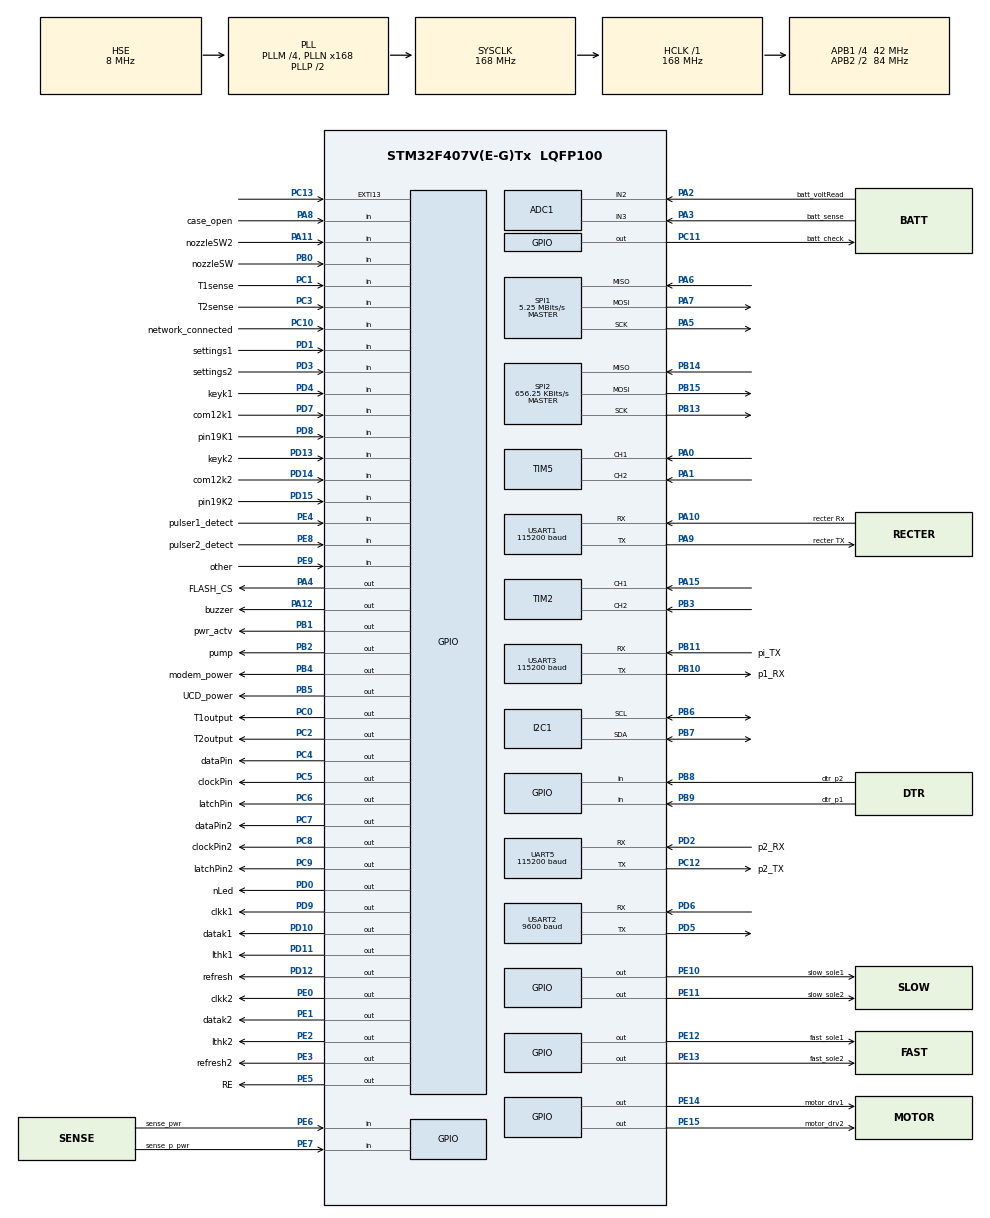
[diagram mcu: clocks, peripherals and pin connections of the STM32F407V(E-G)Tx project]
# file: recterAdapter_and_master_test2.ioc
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ADC1.Channel-1\#ChannelRegularConversion=ADC_CHANNEL_2
ADC1.ContinuousConvMode=ENABLE
ADC1.DMAContinuousRequests=DISABLE
ADC1.NbrOfConversion=1
ADC1.NbrOfConversionFlag=1
ADC1.Rank-1\#ChannelRegularConversion=1
ADC1.SamplingTime-1\#ChannelRegularConversion=ADC_SAMPLETIME_28CYCLES
ADC1.ScanConvMode=ENABLE
ADC1.master=1
Dma.ADC1.0.Direction=DMA_PERIPH_TO_MEMORY
Dma.ADC1.0.FIFOMode=DMA_FIFOMODE_DISABLE
Dma.ADC1.0.Instance=DMA2_Stream0
Dma.ADC1.0.MemDataAlignment=DMA_MDATAALIGN_HALFWORD
Dma.ADC1.0.MemInc=DMA_MINC_ENABLE
Dma.ADC1.0.Mode=DMA_CIRCULAR
Dma.ADC1.0.PeriphDataAlignment=DMA_PDATAALIGN_HALFWORD
Dma.ADC1.0.PeriphInc=DMA_PINC_DISABLE
Dma.ADC1.0.Priority=DMA_PRIORITY_LOW
Dma.Request0=ADC1
Dma.Request1=USART2_RX
Dma.Request2=USART2_TX
Dma.USART2_RX.1.Direction=DMA_PERIPH_TO_MEMORY
Dma.USART2_RX.1.FIFOMode=DMA_FIFOMODE_DISABLE
Dma.USART2_RX.1.Instance=DMA1_Stream5
Dma.USART2_RX.1.MemDataAlignment=DMA_MDATAALIGN_BYTE
Dma.USART2_RX.1.MemInc=DMA_MINC_ENABLE
Dma.USART2_RX.1.Mode=DMA_NORMAL
Dma.USART2_RX.1.PeriphDataAlignment=DMA_PDATAALIGN_BYTE
Dma.USART2_RX.1.PeriphInc=DMA_PINC_DISABLE
Dma.USART2_RX.1.Priority=DMA_PRIORITY_LOW
Dma.USART2_TX.2.Direction=DMA_MEMORY_TO_PERIPH
Dma.USART2_TX.2.FIFOMode=DMA_FIFOMODE_DISABLE
Dma.USART2_TX.2.Instance=DMA1_Stream6
Dma.USART2_TX.2.MemDataAlignment=DMA_MDATAALIGN_BYTE
Dma.USART2_TX.2.MemInc=DMA_MINC_ENABLE
Dma.USART2_TX.2.Mode=DMA_NORMAL
Dma.USART2_TX.2.PeriphDataAlignment=DMA_PDATAALIGN_BYTE
Dma.USART2_TX.2.PeriphInc=DMA_PINC_DISABLE
Dma.USART2_TX.2.Priority=DMA_PRIORITY_LOW
IWDG.Prescaler=IWDG_PRESCALER_32
IWDG.Reload=799
Mcu.Family=STM32F4
Mcu.Name=STM32F407V(E-G)Tx
Mcu.Package=LQFP100
NVIC.DMA1_Stream5_IRQn=true\:0\:0\:false\:false\:true\:false\:true\:true
NVIC.DMA1_Stream6_IRQn=true\:0\:0\:false\:false\:true\:false\:true\:true
NVIC.DMA2_Stream0_IRQn=true\:0\:0\:false\:false\:true\:false\:true\:true
NVIC.EXTI15_10_IRQn=true\:0\:0\:false\:false\:true\:true\:true\:true
NVIC.HASH_RNG_IRQn=true\:0\:0\:false\:false\:true\:true\:true\:true
NVIC.I2C1_ER_IRQn=true\:0\:0\:false\:false\:true\:true\:true\:true
NVIC.I2C1_EV_IRQn=true\:0\:0\:false\:false\:true\:true\:true\:true
NVIC.PriorityGroup=NVIC_PRIORITYGROUP_4
NVIC.RTC_WKUP_IRQn=true\:0\:0\:false\:false\:true\:true\:true\:true
NVIC.SPI2_IRQn=true\:0\:0\:false\:false\:true\:true\:true\:true
NVIC.UART5_IRQn=true\:0\:0\:false\:false\:true\:true\:true\:true
NVIC.USART1_IRQn=true\:0\:0\:false\:false\:true\:true\:true\:true
NVIC.USART2_IRQn=true\:0\:0\:false\:false\:true\:true\:true\:true
NVIC.USART3_IRQn=true\:0\:0\:false\:false\:true\:true\:true\:true
PA0-WKUP.Signal=S_TIM5_CH1
PA1.Signal=S_TIM5_CH2
PA10.GPIO_Label=recter Rx
PA10.Mode=Asynchronous
PA10.Signal=USART1_RX
PA11.GPIO_Label=nozzleSW2
PA11.GPIO_PuPd=GPIO_PULLUP
PA11.Signal=GPIO_Input
PA12.GPIO_Label=buzzer
PA12.Signal=GPIO_Output
PA13.Mode=Serial_Wire
PA13.Signal=SYS_JTMS-SWDIO
PA14.Mode=Serial_Wire
PA14.Signal=SYS_JTCK-SWCLK
PA15.Signal=S_TIM2_CH1_ETR
PA2.GPIO_Label=batt_voltRead
PA2.Signal=ADCx_IN2
PA3.GPIO_Label=batt_sense
PA3.Signal=ADCx_IN3
PA4.GPIO_Label=FLASH_CS
PA4.PinState=GPIO_PIN_SET
PA4.Signal=GPIO_Output
PA5.Mode=Full_Duplex_Master
PA5.Signal=SPI1_SCK
PA6.Mode=Full_Duplex_Master
PA6.Signal=SPI1_MISO
PA7.Mode=Full_Duplex_Master
PA7.Signal=SPI1_MOSI
PA8.GPIO_Label=case_open
PA8.Signal=GPIO_Input
PA9.GPIO_Label=recter TX
PA9.Mode=Asynchronous
PA9.Signal=USART1_TX
PB0.GPIO_Label=nozzleSW
PB0.GPIO_PuPd=GPIO_PULLUP
PB0.Signal=GPIO_Input
PB1.GPIO_Label=pwr_actv
PB1.Signal=GPIO_Output
PB10.GPIO_Label=p1_RX
PB10.Mode=Asynchronous
PB10.Signal=USART3_TX
PB11.GPIO_Label=pi_TX
PB11.Mode=Asynchronous
PB11.Signal=USART3_RX
PB12.Signal=SPI2_NSS
PB13.Mode=Full_Duplex_Master
PB13.Signal=SPI2_SCK
PB14.Mode=Full_Duplex_Master
PB14.Signal=SPI2_MISO
PB15.Mode=Full_Duplex_Master
PB15.Signal=SPI2_MOSI
PB2.GPIO_Label=pump
PB2.Signal=GPIO_Output
PB3.Signal=S_TIM2_CH2
PB4.GPIO_Label=modem_power
PB4.Signal=GPIO_Output
PB5.GPIO_Label=UCD_power
PB5.Signal=GPIO_Output
PB6.Mode=I2C
PB6.Signal=I2C1_SCL
PB7.Mode=I2C
PB7.Signal=I2C1_SDA
PB8.GPIO_Label=dtr_p2
PB8.GPIO_PuPd=GPIO_PULLUP
PB8.Signal=GPIO_Input
PB9.GPIO_Label=dtr_p1
PB9.GPIO_PuPd=GPIO_PULLUP
PB9.Signal=GPIO_Input
PC0.GPIO_Label=T1output
PC0.Signal=GPIO_Output
PC1.GPIO_Label=T1sense
PC1.Signal=GPIO_Input
PC10.GPIO_Label=network_connected
PC10.GPIO_PuPd=GPIO_PULLDOWN
PC10.Signal=GPIO_Input
PC11.GPIO_Label=batt_check
PC11.Signal=GPIO_Output
PC12.GPIO_Label=p2_TX
PC12.Mode=Asynchronous
PC12.Signal=UART5_TX
PC13-ANTI_TAMP.Signal=GPXTI13
PC14-OSC32_IN.Mode=LSE-External-Oscillator
PC14-OSC32_IN.Signal=RCC_OSC32_IN
PC15-OSC32_OUT.Mode=LSE-External-Oscillator
PC15-OSC32_OUT.Signal=RCC_OSC32_OUT
PC2.GPIO_Label=T2output
PC2.Signal=GPIO_Output
PC3.GPIO_Label=T2sense
PC3.Signal=GPIO_Input
PC4.GPIO_Label=dataPin
PC4.Signal=GPIO_Output
PC5.GPIO_Label=clockPin
PC5.Signal=GPIO_Output
PC6.GPIO_Label=latchPin
PC6.Signal=GPIO_Output
PC7.GPIO_Label=dataPin2
PC7.Signal=GPIO_Output
PC8.GPIO_Label=clockPin2
PC8.Signal=GPIO_Output
PC9.GPIO_Label=latchPin2
PC9.Signal=GPIO_Output
PD0.GPIO_Label=nLed
PD0.Signal=GPIO_Output
PD1.GPIO_Label=settings1
PD1.GPIO_PuPd=GPIO_PULLUP
PD1.Signal=GPIO_Input
PD10.GPIO_Label=datak1
PD10.Signal=GPIO_Output
PD11.GPIO_Label=lthk1
PD11.Signal=GPIO_Output
PD12.GPIO_Label=refresh
PD12.Signal=GPIO_Output
PD13.GPIO_Label=keyk2
PD13.GPIO_PuPd=GPIO_PULLUP
PD13.Signal=GPIO_Input
PD14.GPIO_Label=com12k2
PD14.GPIO_PuPd=GPIO_PULLUP
PD14.Signal=GPIO_Input
PD15.GPIO_Label=pin19K2
PD15.GPIO_PuPd=GPIO_PULLUP
PD15.Signal=GPIO_Input
PD2.GPIO_Label=p2_RX
PD2.Mode=Asynchronous
PD2.Signal=UART5_RX
PD3.GPIO_Label=settings2
PD3.GPIO_PuPd=GPIO_PULLUP
PD3.Signal=GPIO_Input
PD4.GPIO_Label=keyk1
PD4.GPIO_PuPd=GPIO_PULLUP
PD4.Signal=GPIO_Input
PD5.Mode=Asynchronous
PD5.Signal=USART2_TX
PD6.Mode=Asynchronous
PD6.Signal=USART2_RX
PD7.GPIO_Label=com12k1
PD7.GPIO_PuPd=GPIO_PULLUP
PD7.Signal=GPIO_Input
PD8.GPIO_Label=pin19K1
PD8.GPIO_PuPd=GPIO_PULLUP
PD8.Signal=GPIO_Input
PD9.GPIO_Label=clkk1
PD9.Signal=GPIO_Output
PE0.GPIO_Label=clkk2
PE0.Signal=GPIO_Output
PE1.GPIO_Label=datak2
PE1.Signal=GPIO_Output
PE10.GPIO_Label=slow_sole1
PE10.PinState=GPIO_PIN_RESET
PE10.Signal=GPIO_Output
PE11.GPIO_Label=slow_sole2
PE11.PinState=GPIO_PIN_RESET
PE11.Signal=GPIO_Output
PE12.GPIO_Label=fast_sole1
PE12.PinState=GPIO_PIN_RESET
PE12.Signal=GPIO_Output
PE13.GPIO_Label=fast_sole2
PE13.PinState=GPIO_PIN_RESET
PE13.Signal=GPIO_Output
PE14.GPIO_Label=motor_drv1
PE14.PinState=GPIO_PIN_RESET
PE14.Signal=GPIO_Output
PE15.GPIO_Label=motor_drv2
PE15.PinState=GPIO_PIN_RESET
PE15.Signal=GPIO_Output
PE2.GPIO_Label=lthk2
PE2.Signal=GPIO_Output
PE3.GPIO_Label=refresh2
PE3.Signal=GPIO_Output
PE4.GPIO_Label=pulser1_detect
PE4.Signal=GPIO_Input
PE5.GPIO_Label=RE
PE5.Signal=GPIO_Output
PE6.GPIO_Label=sense_pwr
PE6.GPIO_PuPd=GPIO_PULLUP
PE6.Signal=GPIO_Input
PE7.GPIO_Label=sense_p_pwr
PE7.GPIO_PuPd=GPIO_NOPULL
PE7.Signal=GPIO_Input
PE8.GPIO_Label=pulser2_detect
PE8.Signal=GPIO_Input
PE9.GPIO_Label=other
PE9.Signal=GPIO_Input
PH0-OSC_IN.Mode=HSE-External-Oscillator
PH0-OSC_IN.Signal=RCC_OSC_IN
PH1-OSC_OUT.Mode=HSE-External-Oscillator
PH1-OSC_OUT.Signal=RCC_OSC_OUT
ProjectManager.HeapSize=0x1890
ProjectManager.StackSize=0x1AD0
ProjectManager.TargetToolchain=STM32CubeIDE
RCC.48MHZClocksFreq_Value=48000000
RCC.AHBFreq_Value=168000000
RCC.APB1CLKDivider=RCC_HCLK_DIV4
RCC.APB1Freq_Value=42000000
RCC.APB1TimFreq_Value=84000000
RCC.APB2CLKDivider=RCC_HCLK_DIV2
RCC.APB2Freq_Value=84000000
RCC.APB2TimFreq_Value=168000000
RCC.CortexFreq_Value=168000000
RCC.HCLKFreq_Value=168000000
RCC.HSE_VALUE=8000000
RCC.HSI_VALUE=16000000
RCC.PLLM=4
RCC.PLLN=168
RCC.PLLQ=7
RCC.PLLSourceVirtual=RCC_PLLSOURCE_HSE
RCC.RCC_RTC_Clock_SourceVirtual=RCC_RTCCLKSOURCE_LSE
RCC.RCC_RTC_Clock_Source_FROM_HSE=RCC_RTCCLKSOURCE_HSE_DIV8
RCC.SYSCLKFreq_VALUE=168000000
RCC.SYSCLKSource=RCC_SYSCLKSOURCE_PLLCLK
RCC.VCOOutputFreq_Value=336000000
RTC.Date=26
RTC.Hours=13
RTC.Month=RTC_MONTH_SEPTEMBER
RTC.Year=22
SH.ADCx_IN2.0=ADC1_IN2,IN2
SH.ADCx_IN3.0=ADC1_IN3,IN3
SH.S_TIM2_CH1_ETR.0=TIM2_CH1,Encoder_Interface
SH.S_TIM2_CH2.0=TIM2_CH2,Encoder_Interface
SH.S_TIM5_CH1.0=TIM5_CH1,Encoder_Interface
SH.S_TIM5_CH2.0=TIM5_CH2,Encoder_Interface
SPI1.BaudRatePrescaler=SPI_BAUDRATEPRESCALER_16
SPI1.CalculateBaudRate=5.25 MBits/s
SPI1.Direction=SPI_DIRECTION_2LINES
SPI1.Mode=SPI_MODE_MASTER
SPI1.VirtualType=VM_MASTER
SPI2.BaudRatePrescaler=SPI_BAUDRATEPRESCALER_64
SPI2.CalculateBaudRate=656.25 KBits/s
SPI2.Direction=SPI_DIRECTION_2LINES
SPI2.Mode=SPI_MODE_MASTER
SPI2.VirtualType=VM_MASTER
TIM2.EncoderMode=TIM_ENCODERMODE_TI12
TIM2.IC1Filter=10
TIM2.IC2Filter=10
TIM5.EncoderMode=TIM_ENCODERMODE_TI12
TIM5.IC1Filter=10
TIM5.IC2Filter=10
UART5.BaudRate=115200
UART5.VirtualMode=Asynchronous
USART1.BaudRate=115200
USART1.VirtualMode=VM_ASYNC
USART2.BaudRate=9600
USART2.Parity=PARITY_ODD
USART2.VirtualMode=VM_ASYNC
USART2.WordLength=WORDLENGTH_9B
USART3.BaudRate=115200
USART3.VirtualMode=VM_ASYNC
VP_IWDG_VS_IWDG.Mode=IWDG_Activate
VP_RNG_VS_RNG.Mode=RNG_Activate
VP_RTC_VS_RTC_Activate.Mode=RTC_Enabled
VP_RTC_VS_RTC_Calendar.Mode=RTC_Calendar
VP_RTC_VS_RTC_WakeUp_intern.Mode=WakeUp
board=custom

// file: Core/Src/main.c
/* USER CODE BEGIN Header */
/**
 ******************************************************************************
 * @file           : main.c
 * @brief          : Main program body
 ******************************************************************************
 * @attention
 *
 * <h2><center>&copy; Copyright (c) 2021 STMicroelectronics.
 * All rights reserved.</center></h2>
 *
 * This software component is licensed by ST under BSD 3-Clause license,
 * the "License"; You may not use this file except in compliance with the
 * License. You may obtain a copy of the License at:
 *                        opensource.org/licenses/BSD-3-Clause
 *
 ******************************************************************************
 */
/* USER CODE END Header */
#include "main.h"

/* USER CODE BEGIN Includes */

#include "thread1.h"
#include "interrupt_codes.h"
#include "write__.h"
#include "stdio.h"
#include "myLibraries.h"
#include "string.h"
#include "stdbool.h"

#include "UartRingbuffer.h"

#include "core_cm4.h" // CMSIS header for Cortex-M4

/* USER CODE END Includes */

ADC_HandleTypeDef hadc1;
DMA_HandleTypeDef hdma_adc1;

I2C_HandleTypeDef hi2c1;

IWDG_HandleTypeDef hiwdg;

RNG_HandleTypeDef hrng;

RTC_HandleTypeDef hrtc;

SPI_HandleTypeDef hspi1;
SPI_HandleTypeDef hspi2;

TIM_HandleTypeDef htim2;
TIM_HandleTypeDef htim5;

UART_HandleTypeDef huart5;
UART_HandleTypeDef huart1;
UART_HandleTypeDef huart2;
UART_HandleTypeDef huart3;
DMA_HandleTypeDef hdma_usart2_rx;
DMA_HandleTypeDef hdma_usart2_tx;

/* USER CODE BEGIN PV */
extern uint32_t pulser1;
extern uint32_t pulser2;
extern char prn[40];

extern pump_settings_stream1 settings_stream1[2];
extern pump_settings_stream2 settings_stream2[2];

//uint8_t dummyValue = 0;

ADC_ChannelConfTypeDef sConfig = {0};

uint32_t start_cycles = 0,
		 end_cycles = 0,
		 elapsed_cycles = 0;

float time_us = 0.0; // Time in microseconds

/* USER CODE END PV */

void SystemClock_Config(void);
static void MX_GPIO_Init(void);
static void MX_DMA_Init(void);
static void MX_I2C1_Init(void);
static void MX_RTC_Init(void);
static void MX_SPI1_Init(void);
static void MX_SPI2_Init(void);
static void MX_TIM2_Init(void);
static void MX_TIM5_Init(void);
static void MX_USART1_UART_Init(void);
static void MX_USART2_UART_Init(void);
static void MX_ADC1_Init(void);
static void MX_USART3_UART_Init(void);
static void MX_UART5_Init(void);
static void MX_RNG_Init(void);
static void MX_IWDG_Init(void);
/* USER CODE BEGIN PFP */

// This array hold the the channels ADC value
volatile uint16_t adc_dma_result[2];
// This variable calculate the array length.
// In our case, array size in 3
int adc_channel_count = sizeof(adc_dma_result)/sizeof(adc_dma_result[0]);
// This flag will help to detect
// the DMA conversion completed or not
uint8_t adc_conv_complete_flag = 0;

// This character buffer array will
// store the result after conversion complete
char dma_result_buffer[100];

/* USER CODE END PFP */

/* USER CODE BEGIN 0 */
//uint8_t data[100];
//
//void HAL_UART_TxCpltCallback(UART_HandleTypeDef *huart)
//{
//   HAL_UART_Transmit_IT(&huart1, data, sizeof (data));
//}

//#define RxBuf_SIZE   512
//#define MainBuf_SIZE 2048

uint8_t RxBuf[RxBuf_SIZE],
		MainBuf[MainBuf_SIZE],
		SOP,  //Start-Of-Packet
		SOP2;

uint8_t go_buff[RxBuf_SIZE];

uint16_t oldPos = 0,
		 newPos = 0;

bool go_message = false;

int16_t head = 0,
		tail = 0;

int milliseconds = 0;

unsigned int cheq1 = 0;

extern unsigned long t_exec1,
					 t_exec2,
					 t_exec3,
					 t_exec4,
					 t_exec5,
					 t_exec6,
					 t_exec7,
					 t_exec8,
					 t_exec9;

//int isOK = 0;

extern unsigned char pumpno,
					 pumpno2;

void HAL_UARTEx_RxEventCallback(UART_HandleTypeDef *huart, uint16_t Size)
{
	SOP = settings_stream1[0].noz_addr + 0x4F;
	SOP2 = settings_stream1[1].noz_addr + 0x4F;

	if (huart->Instance == USART2)
	{
		oldPos = newPos;  // Update the last position before copying new data

		/* If the data in large and it is about to exceed the buffer size, we have to route it to the start of the buffer
		 * This is to maintain the circular buffer
		 * The old data in the main buffer will be overlapped
		 */
		if (oldPos+Size > MainBuf_SIZE)  // If the current position + new data size is greater than the main buffer
		{
			uint16_t datatocopy = MainBuf_SIZE-oldPos;  // find out how much space is left in the main buffer
			memcpy ((uint8_t *)MainBuf+oldPos, RxBuf, datatocopy);  // copy data in that remaining space

			oldPos = 0;  // point to the start of the buffer
			memcpy ((uint8_t *)MainBuf, (uint8_t *)RxBuf+datatocopy, (Size-datatocopy));  // copy the remaining data
			newPos = (Size-datatocopy);  // update the position
		}

		/* if the current position + new data size is less than the main buffer
		 * we will simply copy the data into the buffer and update the position
		 */
		else
		{
			memcpy ((uint8_t *)MainBuf+oldPos, RxBuf, Size);
			newPos = Size+oldPos;
		}

		head = newPos - Size;
		tail = newPos - 1;

		if (head < 0)  //checks for a wrap-around / overflow
		{
			head = MainBuf_SIZE - Size;
		}

		if( (MainBuf[tail] == 0xFA) && ( (MainBuf[head] == SOP) || (MainBuf[head] == SOP2) ) )
		{
			go_message = true;
			cheq1++;
		}

//		go_message = true;

		/* start the DMA again */
		HAL_UARTEx_ReceiveToIdle_DMA(&huart2, (uint8_t *) RxBuf, RxBuf_SIZE);
		__HAL_DMA_DISABLE_IT(&hdma_usart2_rx, DMA_IT_HT);

	}

//	HAL_UART_Transmit_DMA(&huart2, "Hi, WifiBoard!", 14);

	/****************** PROCESS (Little) THE DATA HERE *********************/

//	/* Let's say we want to check for the keyword "OK" within our incoming DATA */
//	for (int i=0; i<Size; i++)
//	{
//		if ((RxBuf[i] == 'O') && (RxBuf[i+1] == 'K'))
//		{
//			isOK = 1;
//		}
//	}

}

uint8_t END_MSG[35] = "Overflow Reached! Counter Reset!\n\r";

char buffer[5];

void HAL_GPIO_EXTI_Callback(uint16_t GPIO_Pin)
{
	if (GPIO_Pin == GPIO_PIN_13)
	{
		SystemClock_Config();
		HAL_ResumeTick();
		char *str = "WAKEUP FROM EXTII\n\n";
		HAL_UART_Transmit(&huart2, (uint8_t *) str, strlen (str), HAL_MAX_DELAY);
//		HAL_PWR_DisableSleepOnExit();
	}
}

void HAL_RTCEx_WakeUpTimerEventCallback(RTC_HandleTypeDef *hrtc)
{
	SystemClock_Config();
	HAL_ResumeTick();
	char *str = "WAKEUP FROM RTC\n\n";
	HAL_UART_Transmit(&huart2, (uint8_t *) str, strlen (str), HAL_MAX_DELAY);
}

// Function to enable DWT cycle counter
void EnableDWT(void) {
    CoreDebug->DEMCR |= CoreDebug_DEMCR_TRCENA_Msk; // Enable trace
    DWT->CYCCNT = 0; // Reset the cycle counter
    DWT->CTRL |= DWT_CTRL_CYCCNTENA_Msk; // Enable the cycle counter
}

/* USER CODE END 0 */

int main(void)
{
  /* USER CODE BEGIN 1 */

	// stop_flow1();

	FuelNozzle nozzle1, nozzle2;
	FuelDispenser dispenser;

	void FuelDispenser_init(FuelDispenser *self,
	                       StateMachine *nozzles[MAX_NOZZLES],
	                       ADC_HandleTypeDef *adc)
	{
	    for(int i = 0; i < MAX_NOZZLES; i++)
	    {
	        self->nozzles[i] = nozzles[i];
	    }
	    self->pressure_sensor = adc;
	}

	void FuelNozzle_ctor(FuelNozzle *self,
            GPIO_TypeDef *valve_port, uint16_t valve_pin,
            TIM_HandleTypeDef *flow_timer, float price)
	{
		self->base.vtable = &nozzle_vtable;
		self->base.current_state = STATE_IDLE;
		self->valve_port = valve_port;
		self->valve_pin = valve_pin;
		self->flow_timer = flow_timer;
		self->unit_price = price;
		HAL_GPIO_WritePin(valve_port, valve_pin, GPIO_PIN_RESET);
	}

	// Create nozzle objects
    FuelNozzle_ctor(&nozzle1, VALVE0_GPIO_Port, VALVE0_Pin, &htim2, 1.50f);
    FuelNozzle_ctor(&nozzle2, VALVE1_GPIO_Port, VALVE1_Pin, &htim3, 1.65f);

    // Create dispenser
    StateMachine *nozzles[] = {(StateMachine *)&nozzle1, (StateMachine *)&nozzle2};
    FuelDispenser_init(&dispenser, nozzles, &hadc1);

	//---------------------------------------------------------------------------------------

//**********************************************************************************************/

    /************************************
     *          dispenser.h             *
     ************************************/
    #pragma once
    #include "stm32f4xx_hal.h"

    #define NUM_NOZZLES 2
    #define PULSES_PER_LITER 1000        // From flow meter specifications
    #define MAX_SAFE_PRESSURE 70.0f      // PSI
    #define DISPENSER_TIMEOUT 300000     // 5 minutes (300,000 ms)

    typedef enum {
        STATE_IDLE,
        STATE_AUTH_REQUIRED,
        STATE_PUMP_READY,
        STATE_DISPENSING,
        STATE_PAYMENT_PENDING,
        STATE_EMERGENCY_STOP
    } NozzleState;

    typedef struct {
        // Hardware handles
    	TIM_HandleTypeDef htim5;
        TIM_HandleTypeDef *flow_timer;
        GPIO_TypeDef *valve_port;
        uint16_t valve_pin;
        GPIO_TypeDef *nozzle_switch_port;
        uint16_t nozzle_switch_pin;
        LCD_HandleTypeDef *display;
        ADC_HandleTypeDef *pressure_adc;

        // State variables
        NozzleState state;
        uint32_t pulse_count;
        float total_liters;
        float price_per_liter;
        uint32_t transaction_id;
        bool authorized;
    } Nozzle;

    typedef struct {
        Nozzle nozzles[NUM_NOZZLES];
        RTC_HandleTypeDef *rtc;
        uint32_t total_transactions;
    } FuelDispenser;

    // VTable for nozzle operations
    typedef struct {
        void (*authorize)(Nozzle *self);
        void (*start_dispensing)(Nozzle *self);
        void (*stop_dispensing)(Nozzle *self);
        void (*emergency_stop)(Nozzle *self);
        void (*update_display)(Nozzle *self);
        void (*process_payment)(Nozzle *self);
    } NozzleVTable;

    void Dispenser_Init(FuelDispenser *disp, TIM_HandleTypeDef *tim1, TIM_HandleTypeDef *tim2,
                       ADC_HandleTypeDef *adc1, ADC_HandleTypeDef *adc2, RTC_HandleTypeDef *rtc);
    void Dispenser_Run(FuelDispenser *disp);

    void Dispenser_Init(FuelDispenser *disp, TIM_HandleTypeDef *tim1, TIM_HandleTypeDef *tim2,
	                   ADC_HandleTypeDef *adc1, ADC_HandleTypeDef *adc2, RTC_HandleTypeDef *rtc) {
	    // Initialize nozzle 1 (Regular fuel)
	    disp->nozzles[0] = (Nozzle){
	        .flow_timer = tim1,
	        .valve_port = VALVE1_GPIO_Port,
	        .valve_pin = VALVE1_Pin,
	        .nozzle_switch_port = NOZZLE1_SW_GPIO_Port,
	        .nozzle_switch_pin = NOZZLE1_SW_Pin,
	        .display = &hlcd1,
	        .pressure_adc = adc1,
	        .state = STATE_IDLE,
	        .price_per_liter = 1.50f,
	        .vtable = &nozzle_ops
	    };

	    // Initialize nozzle 2 (Premium fuel)
	    disp->nozzles[1] = (Nozzle){
	        .flow_timer = tim2,
	        .valve_port = VALVE2_GPIO_Port,
	        .valve_pin = VALVE2_Pin,
	        .nozzle_switch_port = NOZZLE2_SW_GPIO_Port,
	        .nozzle_switch_pin = NOZZLE2_SW_Pin,
	        .display = &hlcd2,
	        .pressure_adc = adc2,
	        .state = STATE_IDLE,
	        .price_per_liter = 1.75f,
	        .vtable = &nozzle_ops
	    };

	    disp->rtc = rtc;
	    disp->total_transactions = 0;

	    // Start flow timers in encoder mode
	    HAL_TIM_Encoder_Start(disp->nozzles[0].flow_timer, TIM_CHANNEL_ALL);
	    HAL_TIM_Encoder_Start(disp->nozzles[1].flow_timer, TIM_CHANNEL_ALL);
	}

	// Dispenser initialization
    Dispenser_Init(&fuelDispenser, &htim2, &htim3, &hadc1, &hadc2, &hrtc);

	//---------------------------------------------------------------------------------------

    //**********************************************************************************************/

	// --------------------------
	// 8. Hardware Abstraction
	// --------------------------
	void hardware_init_nozzles(Nozzle nozzles[NOZZLES]) {
	    for(int i = 0; i < NOZZLES; i++) {
	        nozzles[i] = (Nozzle){
	            .vtable = &nozzle_vtable,
	            .id = i,
	            .state = STATE_IDLE,
	            .price_per_liter = 1.50f
	        };
	    }
	}
	Nozzle nozzles[NOZZLES];

    // Initialize hardware and business logic
    hardware_init_nozzles(nozzles);

	//---------------------------------------------------------------------------------------

	uint8_t MSG[35] = {'\0'};
	uint16_t CounterTicks = 0;

	void FuelDispenser_init(FuelDispenser *disp,
		                       StateMachine *nozzles[MAX_NOZZLES])
	{
		for(int i = 0; i < MAX_NOZZLES; i++)
		{
			self->nozzles[i] = nozzles[i];
		}

		disp->config_mode = 0;
	}

//	CoreDebug->DEMCR |= CoreDebug_DEMCR_TRCENA_Msk;
//	DWT->CYCCNT = 0;
//	DWT->CTRL |= DWT_CTRL_CYCCNTENA_Msk;

//	unsigned long t1 = DWT->CYCCNT;
//	/* do something */
//	unsigned long t2 = DWT->CYCCNT;
//	unsigned long diff = t2 - t1;

//	EnableDWT(); // Enable DWT cycle counter

	// Start measurement
//	start_cycles = DWT->CYCCNT;

//	int millis = HAL_GetTick();

	//===========================================================================

	SCnSCB->ACTLR |= SCnSCB_ACTLR_DISDEFWBUF_Msk; // disable the write buffer
	SCB->SHCSR |= SCB_SHCSR_USGFAULTENA_Msk	| SCB_SHCSR_BUSFAULTENA_Msk
    | SCB_SHCSR_MEMFAULTENA_Msk; 				// Enable Usage-/Bus-/Mem Faults

	//===========================================================================

//  read signature from the backup ram...

//	int demo[12] = {0};
  /* USER CODE END 1 */

  /* MCU Configuration--------------------------------------------------------*/

  /* Reset of all peripherals, Initializes the Flash interface and the Systick. */
  HAL_Init();

  /* Configure the system clock */
  SystemClock_Config();

  /* USER CODE BEGIN SysInit */

//  	  retrieve_settings();

  	EnableDWT(); // Enable DWT cycle counter

  	// Start measurement
  	start_cycles = DWT->CYCCNT;

  /* USER CODE END SysInit */

  /* Initialize all configured peripherals */
  MX_GPIO_Init();
  MX_DMA_Init();
  MX_I2C1_Init();
  MX_RTC_Init();
  MX_SPI1_Init();
  MX_SPI2_Init();
//  MX_TIM2_Init();
//  MX_TIM5_Init();
//  MX_USART1_UART_Init();
//  MX_USART2_UART_Init();
//  MX_ADC1_Init();
//  MX_USART3_UART_Init();
//  MX_UART5_Init();
//  MX_RNG_Init();
//  MX_IWDG_Init();
  /* USER CODE BEGIN 2 */

//#ifndef DEV_MODE
//  MX_IWDG_Init();
//#endif

//  retrieve_settings();    //Retrieves settings prior to Timers Initialisation

  retrieve_settings_fram();  //Retrieves settings prior to Timers Initialisation

  MX_TIM2_Init();
  MX_TIM5_Init();
  MX_USART1_UART_Init();
  MX_USART2_UART_Init();
  MX_ADC1_Init();
  MX_USART3_UART_Init();
  MX_UART5_Init();
  MX_RNG_Init();

#ifndef DEV_MODE
  MX_IWDG_Init();
#endif

  //--------------------------------------

//  	  HAL_GPIO_WritePin(buzzer_GPIO_Port, GPIO_PIN_12, GPIO_PIN_SET);
//	  HAL_Delay(200);
//	  HAL_GPIO_WritePin(buzzer_GPIO_Port, GPIO_PIN_12, GPIO_PIN_RESET);
//	  HAL_Delay(80);
//	  HAL_GPIO_WritePin(buzzer_GPIO_Port, GPIO_PIN_12, GPIO_PIN_SET);
//	  HAL_Delay(500);
//	  HAL_GPIO_WritePin(buzzer_GPIO_Port, GPIO_PIN_12, GPIO_PIN_RESET);

  // Initialize the DMA conversion
//   HAL_ADC_Start_DMA(&hadc1, (uint32_t *) adc_dma_result , adc_channel_count);

//   while(1)
//   {
//   		// when adc_conv_complete_flag is set to 1,
//   		// that means DMA conversion is completed
//   	   if(adc_conv_complete_flag == 1)
//   	   {
//   			  // this snprintf function helps to convert the adc_dma_result array
//   			  // into string and store in dma_result_buffer character array
//   			  snprintf(dma_result_buffer, 100, "CH_1: %d, CH_2: %d\r\n", adc_dma_result[0], adc_dma_result[1]);
//   			  // we just send the dma_result_buffer character array with ADC values
//   			  // to our computer serial terminal software (Tera Term) using UART peripheral of STM32
//   //			  HAL_UART_Transmit(&huart2, (uint8_t *) dma_result_buffer, sizeof(dma_result_buffer), HAL_MAX_DELAY);
//   			  // adc_conv_complete_flag variable is set to 0, because,
//   		         // we alert this flag variable for new DMA conversion completion
//   			 adc_conv_complete_flag = 0;
//   		        // delay for 500 Milliseconds
//   			 HAL_Delay(500);
//   		}
//   	    HAL_Delay(10);
//   }

//  	Ringbuf_init ();

//  	SOP = settings_stream1[0].noz_addr + 0x4F;

  HAL_UARTEx_ReceiveToIdle_DMA(&huart2, RxBuf, RxBuf_SIZE);
   __HAL_DMA_DISABLE_IT(&hdma_usart2_rx, DMA_IT_HT);

//   for (int i=0; i<20; i++)
//   {
//	   HAL_GPIO_TogglePin(nLed_GPIO_Port, nLed_Pin);
//   	   HAL_Delay (200);
//   }

//     char *str = "ABOUT TO GO INTO THE STOP MODE\n\n";
//     HAL_UART_Transmit(&huart2, (uint8_t *)str, strlen (str), HAL_MAX_DELAY);
//
//     /*** RTC WAKEUP TIMER RELATED ****/
//
//     /*## Configure the Wake up timer ###########################################*/
//     /*  RTC Wake-up Interrupt Generation:
//         Wake-up Time Base = (RTC_WAKEUPCLOCK_RTCCLK_DIV /(LSI))
//         ==> WakeUpCounter = Wake-up Time / Wake-up Time Base
//
//         To configure the wake up timer to 5s the WakeUpCounter is set to 0x2710:
//           RTC_WAKEUPCLOCK_RTCCLK_DIV = RTCCLK_Div16 = 16
//           Wake-up Time Base = 16 /(32KHz) = 0.0005 seconds
//           ==> WakeUpCounter = ~5s/0.0005s = 20000 = 0x2710 */
//
//     if (HAL_RTCEx_SetWakeUpTimer_IT(&hrtc, 0x2710, RTC_WAKEUPCLOCK_RTCCLK_DIV16) != HAL_OK)
//     {
//       Error_Handler();
//     }
//
//
//     /*** Suspend the systick before going into stop mode ****/
//     HAL_SuspendTick();
//
//     /*** enable sleep on exit for interrupt only operations ****/
//     HAL_PWR_EnableSleepOnExit();
//
//     /*** ENTER THE STOP MODE ****/
//     HAL_PWR_EnterSTOPMode(PWR_LOWPOWERREGULATOR_ON, PWR_STOPENTRY_WFI);
//
//
//     /*** wake up from stop mode ****/
//
//
//     // disable the RTC wakeup
//     HAL_RTCEx_DeactivateWakeUpTimer(&hrtc);
//
//     for (int i = 0; i < 5; i++)
//     {
////   	  HAL_GPIO_TogglePin(GPIOA, GPIO_PIN_5);
//		  HAL_GPIO_TogglePin(nLed_GPIO_Port, nLed_Pin);
//		  HAL_Delay (1000);
//     }
//
//     char *str2 = "WAKEUP FROM STOP MODE in the MAIN LOOP\n\n";
//     HAL_UART_Transmit(&huart2, (uint8_t *)str2, strlen (str2), HAL_MAX_DELAY);

   /*** Check if the SB flag is set ***/

//     if (__HAL_PWR_GET_FLAG(PWR_FLAG_SB) != RESET)
//     {
//   	  __HAL_PWR_CLEAR_FLAG(PWR_FLAG_SB);  // clear the flag
//
//   	  /** display  the string **/
//   	  char *str = "Wakeup from the STANDBY MODE\n\n";
//   	  HAL_UART_Transmit(&huart2, (uint8_t *)str, strlen (str), HAL_MAX_DELAY);
//
//   	  /** Blink the LED **/
//   	  for (int i=0; i<20; i++)
//   	  {
//   		  HAL_GPIO_TogglePin(GPIOA, GPIO_PIN_5);
//   		  HAL_Delay(200);
//   	  }
//
//   	  /** Disable the WWAKEUP PIN **/
//   	  HAL_PWR_DisableWakeUpPin(PWR_WAKEUP_PIN1);  // disable PA0
//
//   	  /** Deactivate the RTC wakeup  **/
//   	  HAL_RTCEx_DeactivateWakeUpTimer(&hrtc);
//     }
//
//
//     /** Now enter the standby mode **/
//      /* Clear the WU FLAG */
//     __HAL_PWR_CLEAR_FLAG(PWR_FLAG_WU);
//
//      /* clear the RTC Wake UP (WU) flag */
//     __HAL_RTC_WAKEUPTIMER_CLEAR_FLAG(&hrtc, RTC_FLAG_WUTF);
//
//      /* Display the string */
//     char *str = "About to enter the STANDBY MODE\n\n";
//     HAL_UART_Transmit(&huart2, (uint8_t *)str, strlen (str), HAL_MAX_DELAY);
//
//      /* Blink the LED */
//     for (int i=0; i<5; i++)
//     {
//   	  HAL_GPIO_TogglePin(GPIOA, GPIO_PIN_5);
//   	  HAL_Delay(750);
//     }
//
//      /* Enable the WAKEUP PIN */
//     HAL_PWR_EnableWakeUpPin(PWR_WAKEUP_PIN1);
//
//     /* enable the RTC Wakeup */
//       /*  RTC Wake-up Interrupt Generation:
//         Wake-up Time Base = (RTC_WAKEUPCLOCK_RTCCLK_DIV /(LSI))
//         ==> WakeUpCounter = Wake-up Time / Wake-up Time Base
//
//         To configure the wake up timer to 5s the WakeUpCounter is set to 0x2710:
//         RTC_WAKEUPCLOCK_RTCCLK_DIV = RTCCLK_Div16 = 16
//         Wake-up Time Base = 16 /(32KHz) = 0.0005 seconds
//         ==> WakeUpCounter = ~5s/0.0005s = 20000 = 0x2710
//       */
//     if (HAL_RTCEx_SetWakeUpTimer_IT(&hrtc, 0x2710, RTC_WAKEUPCLOCK_RTCCLK_DIV16) != HAL_OK)
//     {
//       Error_Handler();
//     }
//
//      /* one last string to be sure */
//     char *str2 = "STANDBY MODE is ON\n\n";
//     HAL_UART_Transmit(&huart2, (uint8_t *)str2, strlen (str2), HAL_MAX_DELAY);
//
//      /* Finally enter the standby mode */
//     HAL_PWR_EnterSTANDBYMode();
//
//
	setup();
  /* USER CODE END 2 */

  /* Infinite loop */
  /* USER CODE BEGIN WHILE */

	while (1)
	{
	//	 __HAL_TIM_SET_COUNTER(&htim5,4017);
	//	 demo[1000000] = 0;

////		Uart_write(3);
//
//		int i = 0;
//
//		memset(go_buff, 0, RxBuf_SIZE);
//
//		t_exec1 = DWT->CYCCNT;
//
//		while (IsDataAvailable())
//		{
////		  int data = Uart_read();  // read the data in the rx_buffer
////		  Uart_write(data);  // send the data to the uart
//
//		  go_buff[i] = Uart_read();  // read the data in the rx_buffer
//		  i++;
//		}
//
//		t_exec4 = DWT->CYCCNT;
//		t_exec5 = t_exec4 - t_exec1;
//
////		if( (MainBuf[tail] == 0xFA) && (MainBuf[head] == SOP) )
//		if( (go_buff[i - 1] == 0xFA) && (go_buff[0] == SOP) )
//		{
//			go_message = true;
//		}

    /* USER CODE END WHILE */

    /* USER CODE BEGIN 3 */

		   // Read The Counter Ticks Register
//		CounterTicks = TIM2->CNT;
//		// Print The Ticks Count Via UART1
//		sprintf(MSG, "Ticks = %d\n\r", CounterTicks);
//		HAL_UART_Transmit(&huart2, MSG, sizeof(MSG), 100);
//		HAL_Delay(100);

//		HAL_UART_Transmit (&huart2, "Hello!", 6, 1000);
//
//		HAL_Delay(5000);

//		while(1)
//		{
//			 house_keeping();
//			 house_keeping2();
//		}

		run();
	}
  /* USER CODE END 3 */
}

void SystemClock_Config(void)
{
  RCC_OscInitTypeDef RCC_OscInitStruct = {0};
  RCC_ClkInitTypeDef RCC_ClkInitStruct = {0};

  /** Configure the main internal regulator output voltage
  */
  __HAL_RCC_PWR_CLK_ENABLE();
  __HAL_PWR_VOLTAGESCALING_CONFIG(PWR_REGULATOR_VOLTAGE_SCALE1);

  /** Initializes the RCC Oscillators according to the specified parameters
  * in the RCC_OscInitTypeDef structure.
  */
  RCC_OscInitStruct.OscillatorType = RCC_OSCILLATORTYPE_LSI|RCC_OSCILLATORTYPE_HSE
                              |RCC_OSCILLATORTYPE_LSE;
  RCC_OscInitStruct.HSEState = RCC_HSE_ON;
  RCC_OscInitStruct.LSEState = RCC_LSE_ON;
  RCC_OscInitStruct.LSIState = RCC_LSI_ON;
  RCC_OscInitStruct.PLL.PLLState = RCC_PLL_ON;
  RCC_OscInitStruct.PLL.PLLSource = RCC_PLLSOURCE_HSE;
  RCC_OscInitStruct.PLL.PLLM = 4;
  RCC_OscInitStruct.PLL.PLLN = 168;
  RCC_OscInitStruct.PLL.PLLP = RCC_PLLP_DIV2;
  RCC_OscInitStruct.PLL.PLLQ = 7;
  if (HAL_RCC_OscConfig(&RCC_OscInitStruct) != HAL_OK)
  {
    Error_Handler();
  }

  /** Initializes the CPU, AHB and APB buses clocks
  */
  RCC_ClkInitStruct.ClockType = RCC_CLOCKTYPE_HCLK|RCC_CLOCKTYPE_SYSCLK
                              |RCC_CLOCKTYPE_PCLK1|RCC_CLOCKTYPE_PCLK2;
  RCC_ClkInitStruct.SYSCLKSource = RCC_SYSCLKSOURCE_PLLCLK;
  RCC_ClkInitStruct.AHBCLKDivider = RCC_SYSCLK_DIV1;
  RCC_ClkInitStruct.APB1CLKDivider = RCC_HCLK_DIV4;
  RCC_ClkInitStruct.APB2CLKDivider = RCC_HCLK_DIV2;

  if (HAL_RCC_ClockConfig(&RCC_ClkInitStruct, FLASH_LATENCY_5) != HAL_OK)
  {
    Error_Handler();
  }
}

static void MX_ADC1_Init(void)
{

  /* USER CODE BEGIN ADC1_Init 0 */
//
  /* USER CODE END ADC1_Init 0 */

  ADC_ChannelConfTypeDef sConfig = {0};

  /* USER CODE BEGIN ADC1_Init 1 */
//
  /* USER CODE END ADC1_Init 1 */

  /** Configure the global features of the ADC (Clock, Resolution, Data Alignment and number of conversion)
  */
  hadc1.Instance = ADC1;
  hadc1.Init.ClockPrescaler = ADC_CLOCK_SYNC_PCLK_DIV4;
  hadc1.Init.Resolution = ADC_RESOLUTION_12B;
  hadc1.Init.ScanConvMode = ENABLE;
  hadc1.Init.ContinuousConvMode = ENABLE;
  hadc1.Init.DiscontinuousConvMode = DISABLE;
  hadc1.Init.ExternalTrigConvEdge = ADC_EXTERNALTRIGCONVEDGE_NONE;
  hadc1.Init.ExternalTrigConv = ADC_SOFTWARE_START;
  hadc1.Init.DataAlign = ADC_DATAALIGN_RIGHT;
  hadc1.Init.NbrOfConversion = 1;
  hadc1.Init.DMAContinuousRequests = DISABLE;
  hadc1.Init.EOCSelection = ADC_EOC_SINGLE_CONV;
  if (HAL_ADC_Init(&hadc1) != HAL_OK)
  {
    Error_Handler();
  }

  /** Configure for the selected ADC regular channel its corresponding rank in the sequencer and its sample time.
  */
  sConfig.Channel = ADC_CHANNEL_2;
  sConfig.Rank = 1;
  sConfig.SamplingTime = ADC_SAMPLETIME_28CYCLES;
  if (HAL_ADC_ConfigChannel(&hadc1, &sConfig) != HAL_OK)
  {
    Error_Handler();
  }
  /* USER CODE BEGIN ADC1_Init 2 */
//
  /* USER CODE END ADC1_Init 2 */

}

static void MX_I2C1_Init(void)
{

  hi2c1.Instance = I2C1;
  hi2c1.Init.ClockSpeed = 100000;
  hi2c1.Init.DutyCycle = I2C_DUTYCYCLE_2;
  hi2c1.Init.OwnAddress1 = 0;
  hi2c1.Init.AddressingMode = I2C_ADDRESSINGMODE_7BIT;
  hi2c1.Init.DualAddressMode = I2C_DUALADDRESS_DISABLE;
  hi2c1.Init.OwnAddress2 = 0;
  hi2c1.Init.GeneralCallMode = I2C_GENERALCALL_DISABLE;
  hi2c1.Init.NoStretchMode = I2C_NOSTRETCH_DISABLE;
  if (HAL_I2C_Init(&hi2c1) != HAL_OK)
  {
    Error_Handler();
  }

}

static void MX_IWDG_Init(void)
{

  hiwdg.Instance = IWDG;
  hiwdg.Init.Prescaler = IWDG_PRESCALER_32;
  hiwdg.Init.Reload = 799;
  if (HAL_IWDG_Init(&hiwdg) != HAL_OK)
  {
    Error_Handler();
  }

}

static void MX_RNG_Init(void)
{

  hrng.Instance = RNG;
  if (HAL_RNG_Init(&hrng) != HAL_OK)
  {
    Error_Handler();
  }

}

static void MX_RTC_Init(void)
{

  RTC_TimeTypeDef sTime = {0};
  RTC_DateTypeDef sDate = {0};

  /** Initialize RTC Only
  */
  hrtc.Instance = RTC;
  hrtc.Init.HourFormat = RTC_HOURFORMAT_24;
  hrtc.Init.AsynchPrediv = 127;
  hrtc.Init.SynchPrediv = 255;
  hrtc.Init.OutPut = RTC_OUTPUT_DISABLE;
  hrtc.Init.OutPutPolarity = RTC_OUTPUT_POLARITY_HIGH;
  hrtc.Init.OutPutType = RTC_OUTPUT_TYPE_OPENDRAIN;
  if (HAL_RTC_Init(&hrtc) != HAL_OK)
  {
    Error_Handler();
  }

  /* USER CODE BEGIN Check_RTC_BKUP */
             return;
  /* USER CODE END Check_RTC_BKUP */

  /** Initialize RTC and set the Time and Date
  */
  sTime.Hours = 0x13;
  sTime.Minutes = 0x0;
  sTime.Seconds = 0x0;
  sTime.DayLightSaving = RTC_DAYLIGHTSAVING_NONE;
  sTime.StoreOperation = RTC_STOREOPERATION_RESET;
  if (HAL_RTC_SetTime(&hrtc, &sTime, RTC_FORMAT_BCD) != HAL_OK)
  {
    Error_Handler();
  }
  sDate.WeekDay = RTC_WEEKDAY_MONDAY;
  sDate.Month = RTC_MONTH_SEPTEMBER;
  sDate.Date = 0x26;
  sDate.Year = 0x22;

  if (HAL_RTC_SetDate(&hrtc, &sDate, RTC_FORMAT_BCD) != HAL_OK)
  {
    Error_Handler();
  }

  /** Enable the WakeUp
  */
  if (HAL_RTCEx_SetWakeUpTimer_IT(&hrtc, 0, RTC_WAKEUPCLOCK_RTCCLK_DIV16) != HAL_OK)
  {
    Error_Handler();
  }

}

static void MX_SPI1_Init(void)
{

  /* SPI1 parameter configuration*/
  hspi1.Instance = SPI1;
  hspi1.Init.Mode = SPI_MODE_MASTER;
  hspi1.Init.Direction = SPI_DIRECTION_2LINES;
  hspi1.Init.DataSize = SPI_DATASIZE_8BIT;
  hspi1.Init.CLKPolarity = SPI_POLARITY_LOW;
  hspi1.Init.CLKPhase = SPI_PHASE_1EDGE;
  hspi1.Init.NSS = SPI_NSS_SOFT;
  hspi1.Init.BaudRatePrescaler = SPI_BAUDRATEPRESCALER_16;
  hspi1.Init.FirstBit = SPI_FIRSTBIT_MSB;
  hspi1.Init.TIMode = SPI_TIMODE_DISABLE;
  hspi1.Init.CRCCalculation = SPI_CRCCALCULATION_DISABLE;
  hspi1.Init.CRCPolynomial = 10;
  if (HAL_SPI_Init(&hspi1) != HAL_OK)
  {
    Error_Handler();
  }

}

static void MX_SPI2_Init(void)
{

  /* SPI2 parameter configuration*/
  hspi2.Instance = SPI2;
  hspi2.Init.Mode = SPI_MODE_MASTER;
  hspi2.Init.Direction = SPI_DIRECTION_2LINES;
  hspi2.Init.DataSize = SPI_DATASIZE_8BIT;
  hspi2.Init.CLKPolarity = SPI_POLARITY_LOW;
  hspi2.Init.CLKPhase = SPI_PHASE_1EDGE;
  hspi2.Init.NSS = SPI_NSS_SOFT;
  hspi2.Init.BaudRatePrescaler = SPI_BAUDRATEPRESCALER_64;
  hspi2.Init.FirstBit = SPI_FIRSTBIT_MSB;
  hspi2.Init.TIMode = SPI_TIMODE_DISABLE;
  hspi2.Init.CRCCalculation = SPI_CRCCALCULATION_DISABLE;
  hspi2.Init.CRCPolynomial = 10;
  if (HAL_SPI_Init(&hspi2) != HAL_OK)
  {
    Error_Handler();
  }

}

static void MX_TIM2_Init(void)
{

  /* USER CODE BEGIN TIM2_Init 0 */

	TIM_Encoder_InitTypeDef sConfig = {0};
	TIM_MasterConfigTypeDef sMasterConfig = {0};
	TIM_SlaveConfigTypeDef sSlaveConfig = {0};

//	settings_stream2[1].pulser_type_ = quadrature;   //non_quadrature;

  /* USER CODE END TIM2_Init 0 */

//  TIM_Encoder_InitTypeDef sConfig = {0};
//  TIM_MasterConfigTypeDef sMasterConfig = {0};

  /* USER CODE BEGIN TIM2_Init 1 */
////
  /* USER CODE END TIM2_Init 1 */
  htim2.Instance = TIM2;
  htim2.Init.Prescaler = 0;
  htim2.Init.CounterMode = TIM_COUNTERMODE_UP;
  htim2.Init.Period = 4294967295;
  htim2.Init.ClockDivision = TIM_CLOCKDIVISION_DIV1;
  htim2.Init.AutoReloadPreload = TIM_AUTORELOAD_PRELOAD_DISABLE;
//  sConfig.EncoderMode = TIM_ENCODERMODE_TI12;
//  sConfig.IC1Polarity = TIM_ICPOLARITY_RISING;
//  sConfig.IC1Selection = TIM_ICSELECTION_DIRECTTI;
//  sConfig.IC1Prescaler = TIM_ICPSC_DIV1;
//  sConfig.IC1Filter = 10;
//  sConfig.IC2Polarity = TIM_ICPOLARITY_RISING;
//  sConfig.IC2Selection = TIM_ICSELECTION_DIRECTTI;
//  sConfig.IC2Prescaler = TIM_ICPSC_DIV1;
//  sConfig.IC2Filter = 10;
//  if (HAL_TIM_Encoder_Init(&htim2, &sConfig) != HAL_OK)
//  {
//    Error_Handler();
//  }
//  sMasterConfig.MasterOutputTrigger = TIM_TRGO_RESET;
//  sMasterConfig.MasterSlaveMode = TIM_MASTERSLAVEMODE_DISABLE;
//  if (HAL_TIMEx_MasterConfigSynchronization(&htim2, &sMasterConfig) != HAL_OK)
//  {
//    Error_Handler();
//  }
  /* USER CODE BEGIN TIM2_Init 2 */

	if(settings_stream2[1].pulser_type_ == quadrature)
	{
		  sConfig.EncoderMode = TIM_ENCODERMODE_TI12;
		  sConfig.IC1Polarity = TIM_ICPOLARITY_RISING;
		  sConfig.IC1Selection = TIM_ICSELECTION_DIRECTTI;
		  sConfig.IC1Prescaler = TIM_ICPSC_DIV1;
		  sConfig.IC1Filter = 10;
		  sConfig.IC2Polarity = TIM_ICPOLARITY_RISING;
		  sConfig.IC2Selection = TIM_ICSELECTION_DIRECTTI;
		  sConfig.IC2Prescaler = TIM_ICPSC_DIV1;
		  sConfig.IC2Filter = 10;
		  if (HAL_TIM_Encoder_Init(&htim2, &sConfig) != HAL_OK)
		  {
		    Error_Handler();
		  }
		  sMasterConfig.MasterOutputTrigger = TIM_TRGO_RESET;
		  sMasterConfig.MasterSlaveMode = TIM_MASTERSLAVEMODE_DISABLE;
		  if (HAL_TIMEx_MasterConfigSynchronization(&htim2, &sMasterConfig) != HAL_OK)
		  {
		    Error_Handler();
		  }
	}
	else if(settings_stream2[1].pulser_type_ == non_quadrature)
	{
		  if (HAL_TIM_Base_Init(&htim2) != HAL_OK)
		  {
			Error_Handler();
		  }
		  sSlaveConfig.SlaveMode = TIM_SLAVEMODE_EXTERNAL1;
		  sSlaveConfig.InputTrigger = TIM_TS_TI1FP1;
		  sSlaveConfig.TriggerPolarity = TIM_TRIGGERPOLARITY_RISING;
		  sSlaveConfig.TriggerFilter = 0;
		  if (HAL_TIM_SlaveConfigSynchro(&htim2, &sSlaveConfig) != HAL_OK)
		  {
			Error_Handler();
		  }
		  sMasterConfig.MasterOutputTrigger = TIM_TRGO_RESET;
		  sMasterConfig.MasterSlaveMode = TIM_MASTERSLAVEMODE_DISABLE;
		  if (HAL_TIMEx_MasterConfigSynchronization(&htim2, &sMasterConfig) != HAL_OK)
		  {
			Error_Handler();
		  }
	}

  /* USER CODE END TIM2_Init 2 */

}

static void MX_TIM5_Init(void)
{

  /* USER CODE BEGIN TIM5_Init 0 */

	TIM_Encoder_InitTypeDef sConfig = {0};
	TIM_MasterConfigTypeDef sMasterConfig = {0};
	TIM_SlaveConfigTypeDef sSlaveConfig = {0};

//	settings_stream2[0].pulser_type_ = quadrature;   //non_quadrature;
//
  /* USER CODE END TIM5_Init 0 */

//  TIM_Encoder_InitTypeDef sConfig = {0};
//  TIM_MasterConfigTypeDef sMasterConfig = {0};

  /* USER CODE BEGIN TIM5_Init 1 */
//
  /* USER CODE END TIM5_Init 1 */
  htim5.Instance = TIM5;
  htim5.Init.Prescaler = 0;
  htim5.Init.CounterMode = TIM_COUNTERMODE_UP;
  htim5.Init.Period = 4294967295;
  htim5.Init.ClockDivision = TIM_CLOCKDIVISION_DIV1;
  htim5.Init.AutoReloadPreload = TIM_AUTORELOAD_PRELOAD_DISABLE;
//  sConfig.EncoderMode = TIM_ENCODERMODE_TI12;
//  sConfig.IC1Polarity = TIM_ICPOLARITY_RISING;
//  sConfig.IC1Selection = TIM_ICSELECTION_DIRECTTI;
//  sConfig.IC1Prescaler = TIM_ICPSC_DIV1;
//  sConfig.IC1Filter = 10;
//  sConfig.IC2Polarity = TIM_ICPOLARITY_RISING;
//  sConfig.IC2Selection = TIM_ICSELECTION_DIRECTTI;
//  sConfig.IC2Prescaler = TIM_ICPSC_DIV1;
//  sConfig.IC2Filter = 10;
//  if (HAL_TIM_Encoder_Init(&htim5, &sConfig) != HAL_OK)
//  {
//    Error_Handler();
//  }
//  sMasterConfig.MasterOutputTrigger = TIM_TRGO_RESET;
//  sMasterConfig.MasterSlaveMode = TIM_MASTERSLAVEMODE_DISABLE;
//  if (HAL_TIMEx_MasterConfigSynchronization(&htim5, &sMasterConfig) != HAL_OK)
//  {
//    Error_Handler();
//  }
  /* USER CODE BEGIN TIM5_Init 2 */

	if(settings_stream2[0].pulser_type_ == quadrature)
	{
		  sConfig.EncoderMode = TIM_ENCODERMODE_TI12;
		  sConfig.IC1Polarity = TIM_ICPOLARITY_RISING;
		  sConfig.IC1Selection = TIM_ICSELECTION_DIRECTTI;
		  sConfig.IC1Prescaler = TIM_ICPSC_DIV1;
		  sConfig.IC1Filter = 10;
		  sConfig.IC2Polarity = TIM_ICPOLARITY_RISING;
		  sConfig.IC2Selection = TIM_ICSELECTION_DIRECTTI;
		  sConfig.IC2Prescaler = TIM_ICPSC_DIV1;
		  sConfig.IC2Filter = 10;
		  if (HAL_TIM_Encoder_Init(&htim5, &sConfig) != HAL_OK)
		  {
		    Error_Handler();
		  }
		  sMasterConfig.MasterOutputTrigger = TIM_TRGO_RESET;
		  sMasterConfig.MasterSlaveMode = TIM_MASTERSLAVEMODE_DISABLE;
		  if (HAL_TIMEx_MasterConfigSynchronization(&htim5, &sMasterConfig) != HAL_OK)
		  {
		    Error_Handler();
		  }
	}
	else if(settings_stream2[0].pulser_type_ == non_quadrature)
	{
		  if (HAL_TIM_Base_Init(&htim5) != HAL_OK)
		  {
		    Error_Handler();
		  }
		  sSlaveConfig.SlaveMode = TIM_SLAVEMODE_EXTERNAL1;
		  sSlaveConfig.InputTrigger = TIM_TS_TI1FP1;
		  sSlaveConfig.TriggerPolarity = TIM_TRIGGERPOLARITY_RISING;
		  sSlaveConfig.TriggerFilter = 0;
		  if (HAL_TIM_SlaveConfigSynchro(&htim5, &sSlaveConfig) != HAL_OK)
		  {
		    Error_Handler();
		  }
		  sMasterConfig.MasterOutputTrigger = TIM_TRGO_RESET;
		  sMasterConfig.MasterSlaveMode = TIM_MASTERSLAVEMODE_DISABLE;
		  if (HAL_TIMEx_MasterConfigSynchronization(&htim5, &sMasterConfig) != HAL_OK)
		  {
		    Error_Handler();
		  }
	}

  /* USER CODE END TIM5_Init 2 */

}

static void MX_UART5_Init(void)
{

  huart5.Instance = UART5;
  huart5.Init.BaudRate = 115200;
  huart5.Init.WordLength = UART_WORDLENGTH_8B;
  huart5.Init.StopBits = UART_STOPBITS_1;
  huart5.Init.Parity = UART_PARITY_NONE;
  huart5.Init.Mode = UART_MODE_TX_RX;
  huart5.Init.HwFlowCtl = UART_HWCONTROL_NONE;
  huart5.Init.OverSampling = UART_OVERSAMPLING_16;
  if (HAL_UART_Init(&huart5) != HAL_OK)
  {
    Error_Handler();
  }

}

static void MX_USART1_UART_Init(void)
{

  huart1.Instance = USART1;
  huart1.Init.BaudRate = 115200;
  huart1.Init.WordLength = UART_WORDLENGTH_8B;
  huart1.Init.StopBits = UART_STOPBITS_1;
  huart1.Init.Parity = UART_PARITY_NONE;
  huart1.Init.Mode = UART_MODE_TX_RX;
  huart1.Init.HwFlowCtl = UART_HWCONTROL_NONE;
  huart1.Init.OverSampling = UART_OVERSAMPLING_16;
  if (HAL_UART_Init(&huart1) != HAL_OK)
  {
    Error_Handler();
  }

}

static void MX_USART2_UART_Init(void)
{

  huart2.Instance = USART2;
  huart2.Init.BaudRate = 9600;
  huart2.Init.WordLength = UART_WORDLENGTH_9B;
  huart2.Init.StopBits = UART_STOPBITS_1;
  huart2.Init.Parity = UART_PARITY_ODD;
  huart2.Init.Mode = UART_MODE_TX_RX;
  huart2.Init.HwFlowCtl = UART_HWCONTROL_NONE;
  huart2.Init.OverSampling = UART_OVERSAMPLING_16;
  if (HAL_UART_Init(&huart2) != HAL_OK)
  {
    Error_Handler();
  }

}

static void MX_USART3_UART_Init(void)
{

  huart3.Instance = USART3;
  huart3.Init.BaudRate = 115200;
  huart3.Init.WordLength = UART_WORDLENGTH_8B;
  huart3.Init.StopBits = UART_STOPBITS_1;
  huart3.Init.Parity = UART_PARITY_NONE;
  huart3.Init.Mode = UART_MODE_TX_RX;
  huart3.Init.HwFlowCtl = UART_HWCONTROL_NONE;
  huart3.Init.OverSampling = UART_OVERSAMPLING_16;
  if (HAL_UART_Init(&huart3) != HAL_OK)
  {
    Error_Handler();
  }

}

static void MX_DMA_Init(void)
{

  /* DMA controller clock enable */
  __HAL_RCC_DMA2_CLK_ENABLE();
  __HAL_RCC_DMA1_CLK_ENABLE();

  /* DMA interrupt init */
  /* DMA1_Stream5_IRQn interrupt configuration */
  HAL_NVIC_SetPriority(DMA1_Stream5_IRQn, 0, 0);
  HAL_NVIC_EnableIRQ(DMA1_Stream5_IRQn);
  /* DMA1_Stream6_IRQn interrupt configuration */
  HAL_NVIC_SetPriority(DMA1_Stream6_IRQn, 0, 0);
  HAL_NVIC_EnableIRQ(DMA1_Stream6_IRQn);
  /* DMA2_Stream0_IRQn interrupt configuration */
  HAL_NVIC_SetPriority(DMA2_Stream0_IRQn, 0, 0);
  HAL_NVIC_EnableIRQ(DMA2_Stream0_IRQn);

}

static void MX_GPIO_Init(void)
{
  GPIO_InitTypeDef GPIO_InitStruct = {0};

  /* GPIO Ports Clock Enable */
  __HAL_RCC_GPIOE_CLK_ENABLE();
  __HAL_RCC_GPIOC_CLK_ENABLE();
  __HAL_RCC_GPIOH_CLK_ENABLE();
  __HAL_RCC_GPIOA_CLK_ENABLE();
  __HAL_RCC_GPIOB_CLK_ENABLE();
  __HAL_RCC_GPIOD_CLK_ENABLE();

  /*Configure GPIO pin Output Level */
  HAL_GPIO_WritePin(GPIOE, lthk2_Pin|refresh2_Pin|RE_Pin|slow_sole1_Pin
                          |slow_sole2_Pin|fast_sole1_Pin|fast_sole2_Pin|motor_drv1_Pin
                          |motor_drv2_Pin|clkk2_Pin|datak2_Pin, GPIO_PIN_RESET);

  /*Configure GPIO pin Output Level */
  HAL_GPIO_WritePin(GPIOC, T1output_Pin|T2output_Pin|dataPin_Pin|clockPin_Pin
                          |latchPin_Pin|dataPin2_Pin|clockPin2_Pin|latchPin2_Pin
                          |batt_check_Pin, GPIO_PIN_RESET);

  /*Configure GPIO pin Output Level */
  HAL_GPIO_WritePin(FLASH_CS_GPIO_Port, FLASH_CS_Pin, GPIO_PIN_SET);

  /*Configure GPIO pin Output Level */
  HAL_GPIO_WritePin(GPIOB, pwr_actv_Pin|pump_Pin|modem_power_Pin|UCD_power_Pin, GPIO_PIN_RESET);

  /*Configure GPIO pin Output Level */
  HAL_GPIO_WritePin(GPIOD, clkk1_Pin|datak1_Pin|lthk1_Pin|refresh_Pin
                          |nLed_Pin, GPIO_PIN_RESET);

  /*Configure GPIO pin Output Level */
  HAL_GPIO_WritePin(buzzer_GPIO_Port, buzzer_Pin, GPIO_PIN_RESET);

  /*Configure GPIO pins : lthk2_Pin refresh2_Pin RE_Pin slow_sole1_Pin
                           slow_sole2_Pin fast_sole1_Pin fast_sole2_Pin motor_drv1_Pin
                           motor_drv2_Pin clkk2_Pin datak2_Pin */
  GPIO_InitStruct.Pin = lthk2_Pin|refresh2_Pin|RE_Pin|slow_sole1_Pin
                          |slow_sole2_Pin|fast_sole1_Pin|fast_sole2_Pin|motor_drv1_Pin
                          |motor_drv2_Pin|clkk2_Pin|datak2_Pin;
  GPIO_InitStruct.Mode = GPIO_MODE_OUTPUT_PP;
  GPIO_InitStruct.Pull = GPIO_NOPULL;
  GPIO_InitStruct.Speed = GPIO_SPEED_FREQ_LOW;
  HAL_GPIO_Init(GPIOE, &GPIO_InitStruct);

  /*Configure GPIO pins : pulser1_detect_Pin sense_p_pwr_Pin pulser2_detect_Pin other_Pin */
  GPIO_InitStruct.Pin = pulser1_detect_Pin|sense_p_pwr_Pin|pulser2_detect_Pin|other_Pin;
  GPIO_InitStruct.Mode = GPIO_MODE_INPUT;
  GPIO_InitStruct.Pull = GPIO_NOPULL;
  HAL_GPIO_Init(GPIOE, &GPIO_InitStruct);

  /*Configure GPIO pin : sense_pwr_Pin */
  GPIO_InitStruct.Pin = sense_pwr_Pin;
  GPIO_InitStruct.Mode = GPIO_MODE_INPUT;
  GPIO_InitStruct.Pull = GPIO_PULLUP;
  HAL_GPIO_Init(sense_pwr_GPIO_Port, &GPIO_InitStruct);

  /*Configure GPIO pin : PC13 */
  GPIO_InitStruct.Pin = GPIO_PIN_13;
  GPIO_InitStruct.Mode = GPIO_MODE_IT_RISING;
  GPIO_InitStruct.Pull = GPIO_NOPULL;
  HAL_GPIO_Init(GPIOC, &GPIO_InitStruct);

  /*Configure GPIO pins : T1output_Pin T2output_Pin dataPin_Pin clockPin_Pin
                           latchPin_Pin dataPin2_Pin clockPin2_Pin latchPin2_Pin
                           batt_check_Pin */
  GPIO_InitStruct.Pin = T1output_Pin|T2output_Pin|dataPin_Pin|clockPin_Pin
                          |latchPin_Pin|dataPin2_Pin|clockPin2_Pin|latchPin2_Pin
                          |batt_check_Pin;
  GPIO_InitStruct.Mode = GPIO_MODE_OUTPUT_PP;
  GPIO_InitStruct.Pull = GPIO_NOPULL;
  GPIO_InitStruct.Speed = GPIO_SPEED_FREQ_LOW;
  HAL_GPIO_Init(GPIOC, &GPIO_InitStruct);

  /*Configure GPIO pins : T1sense_Pin T2sense_Pin */
  GPIO_InitStruct.Pin = T1sense_Pin|T2sense_Pin;
  GPIO_InitStruct.Mode = GPIO_MODE_INPUT;
  GPIO_InitStruct.Pull = GPIO_NOPULL;
  HAL_GPIO_Init(GPIOC, &GPIO_InitStruct);

  /*Configure GPIO pins : FLASH_CS_Pin buzzer_Pin */
  GPIO_InitStruct.Pin = FLASH_CS_Pin|buzzer_Pin;
  GPIO_InitStruct.Mode = GPIO_MODE_OUTPUT_PP;
  GPIO_InitStruct.Pull = GPIO_NOPULL;
  GPIO_InitStruct.Speed = GPIO_SPEED_FREQ_LOW;
  HAL_GPIO_Init(GPIOA, &GPIO_InitStruct);

  /*Configure GPIO pins : nozzleSW_Pin dtr_p2_Pin dtr_p1_Pin */
  GPIO_InitStruct.Pin = nozzleSW_Pin|dtr_p2_Pin|dtr_p1_Pin;
  GPIO_InitStruct.Mode = GPIO_MODE_INPUT;
  GPIO_InitStruct.Pull = GPIO_PULLUP;
  HAL_GPIO_Init(GPIOB, &GPIO_InitStruct);

  /*Configure GPIO pins : pwr_actv_Pin pump_Pin modem_power_Pin UCD_power_Pin */
  GPIO_InitStruct.Pin = pwr_actv_Pin|pump_Pin|modem_power_Pin|UCD_power_Pin;
  GPIO_InitStruct.Mode = GPIO_MODE_OUTPUT_PP;
  GPIO_InitStruct.Pull = GPIO_NOPULL;
  GPIO_InitStruct.Speed = GPIO_SPEED_FREQ_LOW;
  HAL_GPIO_Init(GPIOB, &GPIO_InitStruct);

  /*Configure GPIO pins : pin19K1_Pin keyk2_Pin com12k2_Pin pin19K2_Pin
                           settings1_Pin settings2_Pin keyk1_Pin com12k1_Pin */
  GPIO_InitStruct.Pin = pin19K1_Pin|keyk2_Pin|com12k2_Pin|pin19K2_Pin
                          |settings1_Pin|settings2_Pin|keyk1_Pin|com12k1_Pin;
  GPIO_InitStruct.Mode = GPIO_MODE_INPUT;
  GPIO_InitStruct.Pull = GPIO_PULLUP;
  HAL_GPIO_Init(GPIOD, &GPIO_InitStruct);

  /*Configure GPIO pins : clkk1_Pin datak1_Pin lthk1_Pin refresh_Pin
                           nLed_Pin */
  GPIO_InitStruct.Pin = clkk1_Pin|datak1_Pin|lthk1_Pin|refresh_Pin
                          |nLed_Pin;
  GPIO_InitStruct.Mode = GPIO_MODE_OUTPUT_PP;
  GPIO_InitStruct.Pull = GPIO_NOPULL;
  GPIO_InitStruct.Speed = GPIO_SPEED_FREQ_LOW;
  HAL_GPIO_Init(GPIOD, &GPIO_InitStruct);

  /*Configure GPIO pin : case_open_Pin */
  GPIO_InitStruct.Pin = case_open_Pin;
  GPIO_InitStruct.Mode = GPIO_MODE_INPUT;
  GPIO_InitStruct.Pull = GPIO_NOPULL;
  HAL_GPIO_Init(case_open_GPIO_Port, &GPIO_InitStruct);

  /*Configure GPIO pin : nozzleSW2_Pin */
  GPIO_InitStruct.Pin = nozzleSW2_Pin;
  GPIO_InitStruct.Mode = GPIO_MODE_INPUT;
  GPIO_InitStruct.Pull = GPIO_PULLUP;
  HAL_GPIO_Init(nozzleSW2_GPIO_Port, &GPIO_InitStruct);

  /*Configure GPIO pin : network_connected_Pin */
  GPIO_InitStruct.Pin = network_connected_Pin;
  GPIO_InitStruct.Mode = GPIO_MODE_INPUT;
  GPIO_InitStruct.Pull = GPIO_PULLDOWN;
  HAL_GPIO_Init(network_connected_GPIO_Port, &GPIO_InitStruct);

  /* EXTI interrupt init*/
  HAL_NVIC_SetPriority(EXTI15_10_IRQn, 0, 0);
  HAL_NVIC_EnableIRQ(EXTI15_10_IRQn);

}

void Error_Handler(void)
{
  /* USER CODE BEGIN Error_Handler_Debug */
	/* User can add his own implementation to report the HAL error return state */
//	__disable_irq();

	NVIC_SystemReset();

	while (1)
	{
	}
  /* USER CODE END Error_Handler_Debug */
}
